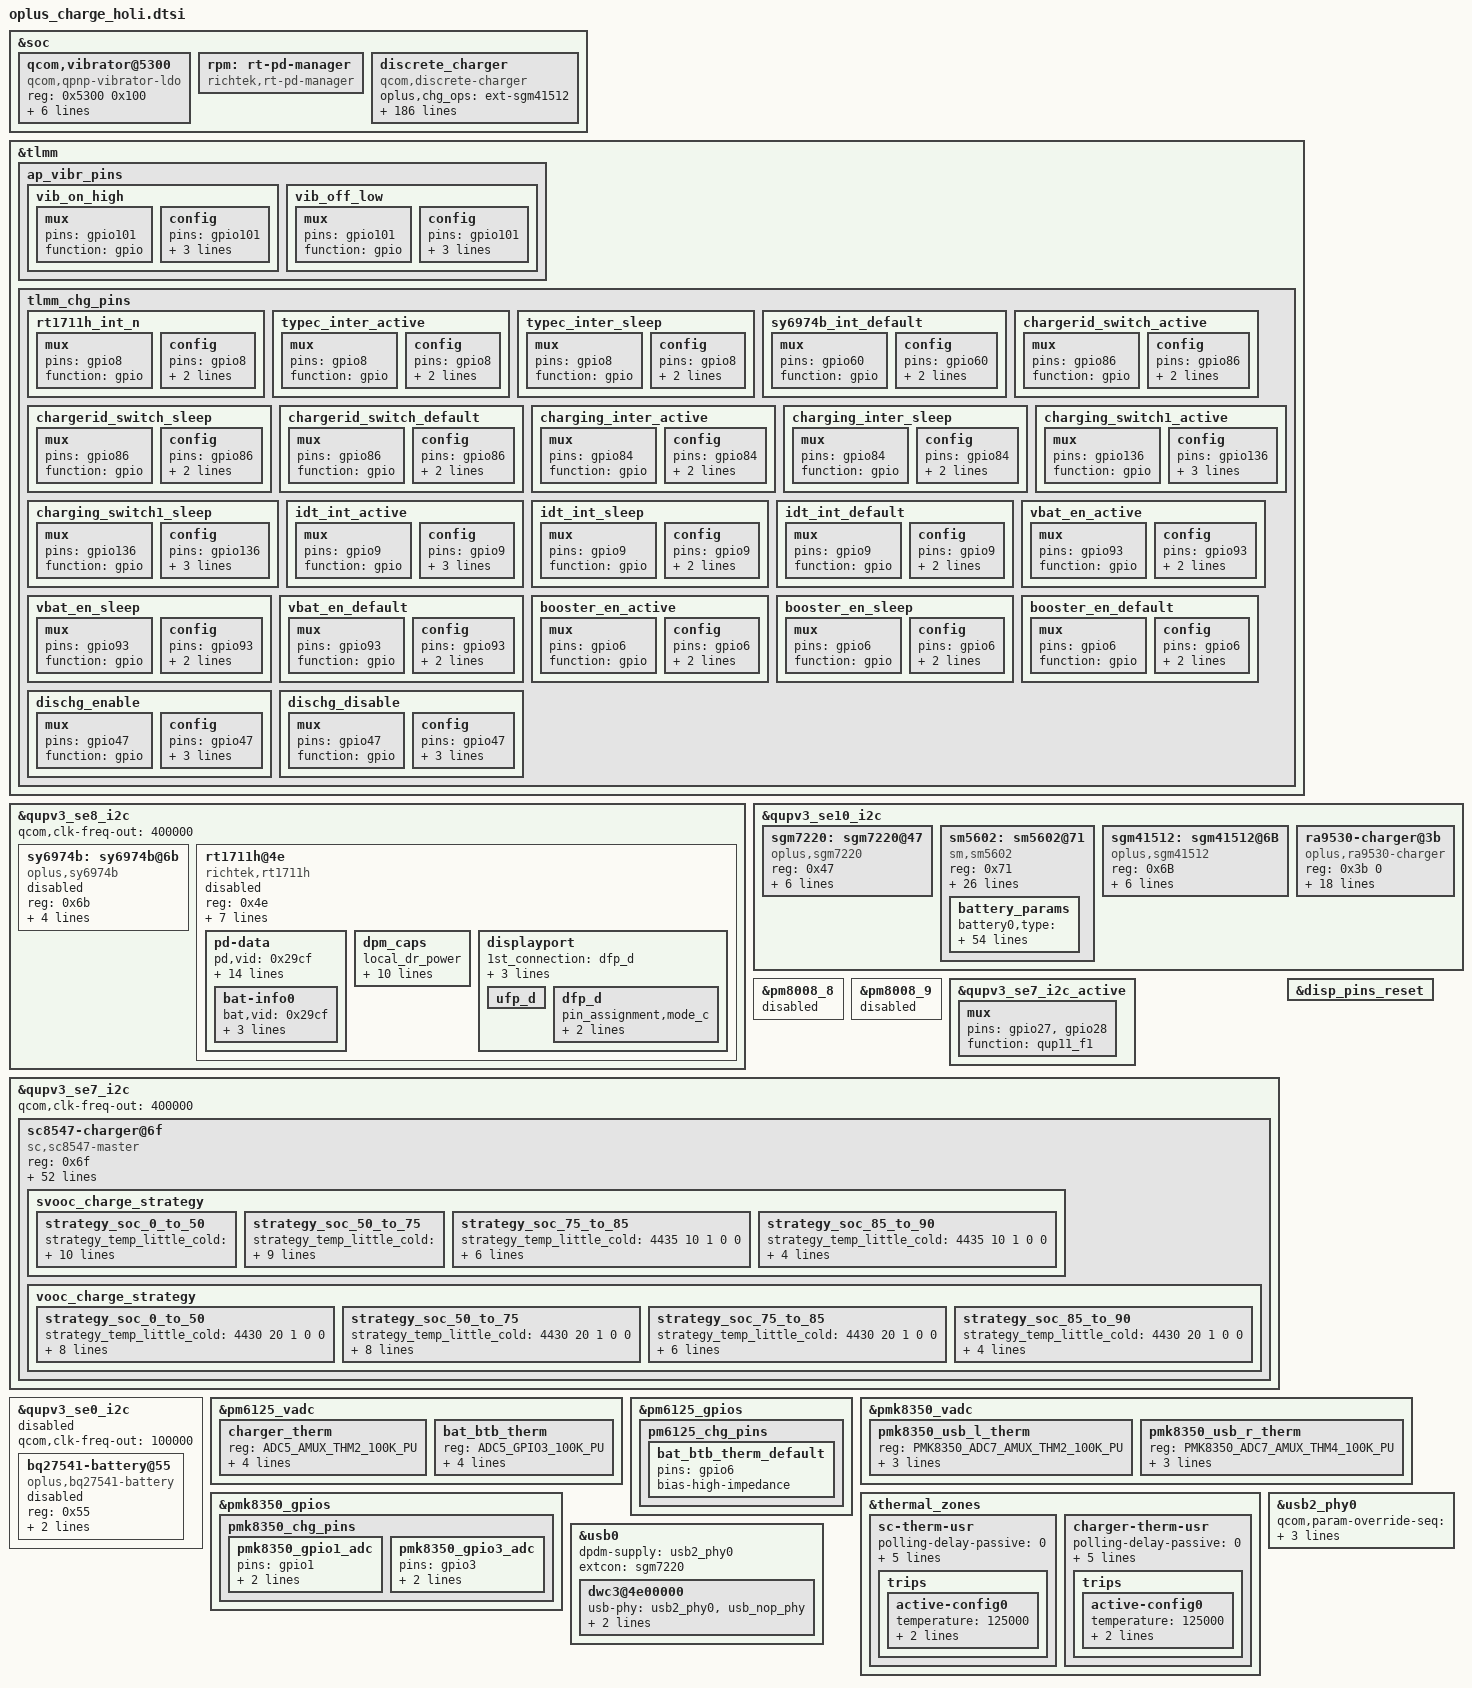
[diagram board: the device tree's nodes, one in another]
#include <dt-bindings/spmi/spmi.h>
#include <dt-bindings/iio/qcom,spmi-vadc.h>

&soc {
	qcom,vibrator@5300 {
		compatible = "qcom,qpnp-vibrator-ldo";
		reg = <0x5300 0x100>;
		qcom,vib-ldo-volt-uv = <3000000>;
		qcom,disable-overdrive;
		qcom,vib-type = <1>;	/*0:ldo 1:gpio*/
		status = "okay";

		qcom,vibrator_switch-gpio = <&tlmm 101 0x00>;
		pinctrl-names = "vib_on_high", "vib_off_low";
		pinctrl-0 = <&vib_on_high>;
		pinctrl-1 = <&vib_off_low >;
	};
};

&tlmm {

	ap_vibr_pins: ap_vibr_pins{
		vib_on_high: vib_on_high{
			mux {
				pins = "gpio101";
				function = "gpio";
			};

			config {
				pins = "gpio101";
				drive-strength = <2>;
				bias-disable;
				output-high;
			};
		};

		vib_off_low: vib_off_low{
			mux {
				pins = "gpio101";
				function = "gpio";
			};

			config {
				pins = "gpio101";
				drive-strength = <2>;
				bias-disable;
				output-high;
			};
		};
	};
};


&qupv3_se8_i2c {
	status = "okay";
	qcom,clk-freq-out = <400000>;
	sy6974b:sy6974b@6b {
		status = "disabled";
		compatible = "oplus,sy6974b";
		reg = <0x6b>;

		sy6974b-irq-gpio = <&tlmm 60 0x00>;
		dpdm-supply = <&usb2_phy0>;
		pinctrl-names = "default";
		pinctrl-0 = <&sy6974b_int_default>;
		qcom,use_real_suspend_6974b;
	};
	rt1711h@4e {
		compatible = "richtek,rt1711h";
		reg = <0x4e>;
		status = "disabled";
		tcpc-dual,supported_modes = <0>; /* 0: dfp/ufp, */
						 /* 1: dfp, 2: ufp */
		rt-tcpc,name = "type_c_port0"; /* tcpc_device's name */
		rt-tcpc,role_def = <1>; /* 0: Unknown, 1: SNK, 2: SRC */
					/* 3: DRP, 4: Try.SRC, 5: Try.SNK */
		rt-tcpc,rp_level = <0>; /* 0: Default, 1: 1.5, 2: 3.0 */
		rt-tcpc,vconn_supply  = <1>;  /* 0: Never, 1: Always, */
					      /* 2: EMarkOnly, 3: StartOnly */
		/* rt-tcpc,disable_pe; */
		//rt1711pd,intr_gpio = <&tlmm 124 0x0>;
		rt1711pd,intr_gpio_num = <124>;
		pinctrl-names = "default";
		pinctrl-0 = <&rt1711h_int_n>;
		pd-data {
			pd,vid = <0x29cf>;
			pd,pid = <0x1711>;
			pd,source-cap-ext = <0x171129cf 0x00000000 0x00000000
					     0x00000000 0x00000000 0x02000000>;
			pd,mfrs = "RichtekTCPC";

			/*
			 *	VSAFE5V = 0, MAX_POWER = 1, CUSTOM = 2,
			 *	MAX_POWER_LV = 0x21, MAX_POWER_LVIC = 0x31
			 *	MAX_POWER_HV = 0x41, MAX_POWER_HVIC = 0x51
			 */
			pd,charging_policy= <0x31>;

			/*
			 * Fixed 5V, 500 mA <0x00019032>
			 * Fixed 5V, 1A <0x00019064>
			 * Fixed 5V, 2A <0x000190c8>
			 * Fixed 5V, 3A <0x0001912c>
			 * Fixed 9V, 500 mA <0x0002d032>
			 * Fixed 9V, 1A <0x0002d064>
			 * Fixed 9V, 2A <0x0002d0c8>
			 * Fixed 9V, 3A <0x0002d12c>
			 * Variable 5-9V, 1A <0x8642d064>
			 * Variable 5-9V, 2A <0x8642d0c8>
			 * Variable 5-9V, 3A <0x8642d12c>
			 * PPS 3V~5.9V, 3A <0xC0761E3C>
			 */
			pd,source-pdo-size = <1>;
			pd,source-pdo-data = <0x00019032>;
			pd,sink-pdo-size = <1>;
			pd,sink-pdo-data = <0x000190c8>;

			/*
			 * No DP, host + device
			 *	pd,id-vdo-size = <6>;
			 *	pd,id-vdo-data = <0xd14029cf 0x0 0x17110000
						  0x41800000 0x0 0x21800000>;
			 * With DP
			 *	pd,id-vdo-size = <6>;
			 *	pd,id-vdo-data = <0xd54029cf 0x0 0x17110000
						  0x41800000 0x0 0x21800000>;
			 */

			pd,id-vdo-size = <6>;
			pd,id-vdo-data = <0xd14029cf 0x0 0x17110000
					  0x41800000 0x0 0x21800000>;

			bat,nr = <1>;
			pd,country_nr = <0>;

			bat-info0 {
				bat,vid = <0x29cf>;
				bat,pid = <0x1711>;
				bat,mfrs = "bat1";
				bat,design_cap = <3000>;
			};

			//bat-info1 {
			//	bat,vid = <0x8abc>;
			//	bat,pid = <0x5234>;
			//	bat,mfrs = "bat2";
			//	bat,design_cap = <4000>;
			//};

			//country0 {
			//	pd,country_code = <0x5457>;
			//	pd,country_len = <2>; /* max len = 26 */
			//	pd,country_data = <0xff 0xff>;
			//};

			//country1 {
			//	pd,country_code = <0x5553>;
			//	pd,country_len = <3>; /* max len = 26 */
			//	pd,country_data = <0xf1 0xf2 0xf3>;
			//};
		};
		dpm_caps {
			local_dr_power;
			local_dr_data;
			//local_ext_power;
			local_usb_comm;
			//local_usb_suspend;
			//local_high_cap;
			//local_give_back;
			local_no_suspend;
			local_vconn_supply;

			//attemp_discover_cable_dfp;
			attemp_enter_dp_mode;
			attemp_discover_cable;
			attemp_discover_id;
			attemp_discover_svid;

			/* 0: disable, 1: prefer_snk, 2: prefer_src */
			pr_check = <0>;
			//pr_reject_as_source;
			//pr_reject_as_sink;
			//pr_check_gp_source;
			//pr_check_gp_sink;

			/* 0: disable, 1: prefer_ufp, 2: prefer_dfp */
			dr_check = <0>;
			//dr_reject_as_dfp;
			//dr_reject_as_ufp;
		};
		displayport {
			/* connection type = "both", "ufp_d", "dfp_d" */
			1st_connection = "dfp_d";
			2nd_connection = "dfp_d";
			signal,dp_v13;
			//signal,dp_gen2;
			//usbr20_not_used;
			typec,receptacle;
			ufp_d {
				//pin_assignment,mode_a;
				//pin_assignment,mode_b;
				//pin_assignment,mode_c;
				//pin_assignment,mode_d;
				//pin_assignment,mode_e;
			};
			dfp_d {
				//pin_assignment,mode_a;
				//pin_assignment,mode_b;
				pin_assignment,mode_c;
				pin_assignment,mode_d;
				pin_assignment,mode_e;
				//pin_assignment,mode_f;
			};
		};
	};
};

/*
*CCLOGIC & SWITCH bring up for Tyr. Add by xukai@vanyol.com
*/
&qupv3_se10_i2c {
        status = "okay";
	sgm7220:sgm7220@47 {
                status = "okay";
                compatible = "oplus,sgm7220";
                reg = <0x47>;
                interrupt-parent = <&tlmm>;
                interrupts = <8 0>;
                interrupt-names = "sgm7220_int_irq";
                sgm7220,irq_gpio = <&tlmm 8 0x8008>;
                //sgm7220,reset-gpio = <&tlmm 12 0x0>;

                //typec irq
                pinctrl-names = "typec_inter_active", "typec_inter_sleep";
                pinctrl-0 = <&typec_inter_active>;
                pinctrl-1 = <&typec_inter_sleep>;

                //headphone det notifiy
                oplus,headphone-det-support = <1>;
       };

       sm5602:sm5602@71 {
		compatible = "sm,sm5602";
		reg = <0x71>;
		interrupt-parent = <&tlmm>;
		interrupts = <50 2>;
		qcom,irq-gpio = <&tlmm 50 0x0>;
		io-channels = <&pm6125_vadc ADC5_GPIO3_100K_PU>;
		io-channel-names = "bat_id_chan";
		sm,en_temp_ex;
		//sm,en_temp_in;
		sm,en_batt_det;
		//sm,iocv_man_mode;
		sm,misc = <0x0800>;
		sm,aging_ctrl = <0x0121>;
		sm,cycle_cfg = <0x7000>;
		sm,rsns = <0>;
		sm,fg_irq_set = <0x07FF>;
		sm,low_soc1 = <1>;
		sm,low_soc2 = <15>;
		sm,v_l_alarm = <3400>;
		sm,v_h_alarm = <4450>;
		sm,battery_table_num = <0>;
		sm,param_version = <4>;
		sm,t_l_alarm_in = <54>;
		sm,t_h_alarm_in = <1>;
		sm,t_l_alarm_ex = <0xD3D8>;
		sm,t_h_alarm_ex = <0x9245>;
		sm,rtrace = <4700>;
		sm,battery_id_num = <0 1>;
		sm,battery_id_resistance = <67 15>;
		sm,battery_id_temp = <33000 70000>;
		sm,check_battery_id;
		battery_params {
			battery0,type = "ATL 2868C7 1S2P 3.87V 8080mAh Rechargeable Li-ion Polymer Battery";
			battery0,param_version = <7>;
			battery0,max_voltage_uv = <4450000>;
			battery0,battery_type = <4450 0x0 0x3E88>;
			battery0,battery_table0 = <0x1400 0x1B33 0x1C25 0x1CEC 0x1D68 0x1D85 0x1D8E 0x1D92 0x1DD0 0x1E04 0x1E4E 0x1E6E 0x1EA6 0x1ED7 0x1F15 0x1F43 0x1F94 0x1FF1 0x2052 0x20F4 0x216D 0x2204 0x22FA 0x24CC>;
			battery0,battery_table1 = <0x0 0x66 0x199 0x334 0x4CF 0x5E1 0x916 0xAB1 0x100A 0x1563 0x1D68 0x22C1 0x2AC7 0x3020 0x3579 0x3826 0x3AD2 0x402B 0x4584 0x4D8A 0x52E3 0x594D 0x6400 0x64E6>;
			battery0,battery_table2 = <0x2A4D 0x181E 0x1214 0x0D0F 0x0B0C 0x0A0B 0x090A 0x0909>;
			battery0,alpha = <0x00CC>;
			battery0,beta = <0x0025>;
			battery0,rs = <0x005F>;
			battery0,rs_value = <0x0050 0x00DD 0x3800 0x0048>;
			battery0,vit_period = <0x315A>;
			battery0,volt_cal = <0x8000>;
			battery0,mix_value = <0x0003>;
			battery0,curr_offset = <0x000>;
			battery0,curr_slope = <0x8080>;
			battery0,topoff_soc = <7 1300 100>;
			battery0,temp_std = <25>;
			battery0,temp_offset = <0 11 1 0 8 (-1)>;
			battery0,temp_cal = <0 6 1 11 (-1) 0 6 1 9 1>;
			battery0,ext_temp_cal = <0 2 1 2 1 1 2 3 2 3>;
			battery0,tem_poff = <3400 100>;
			battery0,thermal_table = <0x3B3A 0x3516 0x2F05 0x28F4 0x2323 0x1D80 0x1804 0x12E1 0x0DA7 0x08B3
										0x03D6 0xF6F2 0xF273 0xEE03 0xE9D0 0xE5C7 0xE1E2 0xDE2C 0xDA98 0xD727
										0xD3D8 0xD0B2 0xCDAC 0xCAC8 0xC806 0xC55C 0xC2D0 0xC069 0xBE17 0xBBE1
										0xB9C6 0xB7C0 0xB5D3 0xB400 0xB242 0xB092 0xAEFD 0xAD7C 0xAC06 0xAAA6
										0xA953 0xA814 0xA6DE 0xA5BE 0xA4A5 0xA39C 0xA2A1 0xA1B1 0xA0CB 0x9FF3
										0x9F23 0x9E59 0x9D9A 0x9CE7 0x9C3B 0x9B95 0x9AF7 0x9A62 0x99D2 0x994B
										0x98CB 0x984E 0x97D6 0x9765 0x96FA 0x9693 0x9631 0x95D3 0x9579 0x9523
										0x94CF 0x9481 0x9435 0x93EC 0x93A6 0x9364 0x9325 0x92EA 0x92B1 0x927B
										0x9245 0x9212 0x91E1 0x91B2 0x9185 0x915A 0x9132 0x910B 0x90E6 0x90C2
										0x90A0 0x907E 0x905E 0x9040 0x9022 0x9006 0x8FEA 0x8FD0 0x8FB7 0x8FA0
										0x8F8A>;  					//NTC value(DEC) table -20~80
			battery1,type = "BLT005_CA2868C7FD_8080mAh";
			battery1,param_version = <4>;
			battery1,max_voltage_uv = <4450000>;
			battery1,battery_type = <4450 0x0 0x3FCD>;
			battery1,battery_table0 = <0x1400 0x1B31 0x1C0A 0x1D08 0x1D71 0x1D8C 0x1D95 0x1D9E 0x1DE6 0x1E3B 0x1E51 0x1E6B 0x1EA2 0x1ED1 0x1F12 0x1F46 0x1F88 0x1FE4 0x207A 0x2123 0x21DD 0x22A8 0x22F0 0x24CC>;
			battery1,battery_table1 = <0x0 0x6A 0x176 0x38F 0x522 0x7C1 0xAE6 0xC78 0x11B6 0x1C31 0x1ED0 0x240E 0x2BEB 0x3128 0x3666 0x3905 0x3BA4 0x40E2 0x48BE 0x509B 0x5878 0x60DA 0x6400 0x64E6>;
			battery1,battery_table2 = <0x2E54 0x1A21 0x1416 0x0F11 0x0C0D 0x0B0C 0x0A0A 0x0909>;
			battery1,alpha = <0x00CC>;
			battery1,beta = <0x0025>;
			battery1,rs = <0x005F>;
			battery1,rs_value = <0x0050 0x00DD 0x3800 0x0048>;
			battery1,vit_period = <0x315A>;
			battery1,volt_cal = <0x8000>;
			battery1,mix_value = <0x0003>;
			battery1,curr_offset = <0x000>;
			battery1,curr_slope = <0x8080>;
			battery1,topoff_soc = <7 1300 100>;
			battery1,temp_std = <25>;
			battery1,temp_offset = <0 11 1 0 8 (-1)>;
			battery1,temp_cal = <0 6 1 11 (-1) 0 6 1 9 1>;
			battery1,ext_temp_cal = <0 2 1 2 1 1 2 3 2 3>;
			battery1,tem_poff = <3400 100>;
			battery1,thermal_table = <0x3B3A 0x3516 0x2F05 0x28F4 0x2323 0x1D80 0x1804 0x12E1 0x0DA7 0x08B3
										0x03D6 0xF6F2 0xF273 0xEE03 0xE9D0 0xE5C7 0xE1E2 0xDE2C 0xDA98 0xD727
										0xD3D8 0xD0B2 0xCDAC 0xCAC8 0xC806 0xC55C 0xC2D0 0xC069 0xBE17 0xBBE1
										0xB9C6 0xB7C0 0xB5D3 0xB400 0xB242 0xB092 0xAEFD 0xAD7C 0xAC06 0xAAA6
										0xA953 0xA814 0xA6DE 0xA5BE 0xA4A5 0xA39C 0xA2A1 0xA1B1 0xA0CB 0x9FF3
										0x9F23 0x9E59 0x9D9A 0x9CE7 0x9C3B 0x9B95 0x9AF7 0x9A62 0x99D2 0x994B
										0x98CB 0x984E 0x97D6 0x9765 0x96FA 0x9693 0x9631 0x95D3 0x9579 0x9523
										0x94CF 0x9481 0x9435 0x93EC 0x93A6 0x9364 0x9325 0x92EA 0x92B1 0x927B
										0x9245 0x9212 0x91E1 0x91B2 0x9185 0x915A 0x9132 0x910B 0x90E6 0x90C2
										0x90A0 0x907E 0x905E 0x9040 0x9022 0x9006 0x8FEA 0x8FD0 0x8FB7 0x8FA0
										0x8F8A>;  //NTC value(DEC) table -20~80
	    };
	};
	sgm41512:sgm41512@6B {
	  status = "okay";
	  compatible = "oplus,sgm41512";
	  reg = <0x6B>;
	  interrupt-parent = <&tlmm>;
	  interrupts = <59 0>;
	  sgm41512-irq-gpio = <&tlmm 59 0>;
	  dpdm-supply = <&usb2_phy0>;
	  qcom,slave_charger_enable-gpio = <&tlmm 12 0x00>;
	  qcom,use_voocphy;
	};

	ra9530-charger@3b {
		status = "ok";
		compatible = "oplus,ra9530-charger";
		reg = <0x3b 0>;

		pinctrl-names = "idt_int_active", "idt_int_sleep", "idt_int_default",
						"vbat_en_active", "vbat_en_sleep", "vbat_en_default",
						"booster_en_active", "booster_en_sleep", "booster_en_default";

		pinctrl-0 = <&idt_int_active>;
		pinctrl-1 = <&idt_int_sleep>;
		pinctrl-2 = <&idt_int_default>;
		pinctrl-3 = <&vbat_en_active>;
		pinctrl-4 = <&vbat_en_sleep>;
		pinctrl-5 = <&vbat_en_default>;
		pinctrl-6 = <&booster_en_active>;
		pinctrl-7 = <&booster_en_sleep>;
		pinctrl-8 = <&booster_en_default>;

		qcom,idt_int-gpio = <&tlmm 9 0x00>;
		qcom,vbat_en-gpio = <&tlmm 93 0x00>;
		qcom,booster_en-gpio = <&tlmm 6 0x00>;

		qcom,ocp_threshold = <500>;
		qcom,ovp_threshold = <12000>;
		qcom,lvp_threshold = <4000>;
		qcom,pcop_threshold1 = <700>;
		qcom,pcop_threshold2 = <500>;
		qcom,fod_threshold = <400>;
	};
};

&soc {
	rpm: rt-pd-manager {
		compatible = "richtek,rt-pd-manager";
	};
};

&pm8008_8 {
	status = "disabled";
};

&pm8008_9 {
	status = "disabled";
};

&qupv3_se7_i2c_active {
	mux {
		pins = "gpio27", "gpio28";
		function = "qup11_f1";
	};
};

&qupv3_se7_i2c {
	status = "okay";
	qcom,clk-freq-out = <400000>;

	sc8547-charger@6f{
		status = "okay";
		compatible = "sc,sc8547-master";
		reg = <0x6f>;

		qcom,irq_gpio = <&tlmm 84 0x00>;
		interrupt-parent = <&tlmm>;
		interrupts = <84 0>;

		pinctrl-names = "switch1_act_switch2_act", "switch1_sleep_switch2_sleep",
				"charging_inter_active", "charging_inter_sleep";
		pinctrl-0 = <&charging_switch1_active>;
		pinctrl-1 = <&charging_switch1_sleep>;
		pinctrl-2 = <&charging_inter_active>;
		pinctrl-3 = <&charging_inter_sleep>;

		qcom,external_gauge_support;
		qcom,charging_switch1-gpio = <&tlmm 136 0x00>;

		qcom,voocphy_current_default = <30>;

		qcom,svooc_cool_down_current_limit = <100 20 20 20 30 40 50 60 70 80 90 100>;
		qcom,vooc_cool_down_current_limit = <60 20 20 20 30 40 50 60>;

		qcom,vooc_little_cold_full_voltage = <4430>;
		qcom,vooc_cool_full_voltage = <4430>;
		qcom,vooc_1time_full_voltage = <4480>;
		qcom,vooc_ntime_full_voltage = <4480>;
		qcom,low_curr_full_t1 = <120>;
		qcom,low_curr_full_t2 = <350>;
		qcom,low_curr_full_t3 = <430>;
		qcom,range1_low_curr_full = <1150 4470
						1050 4465
						950 4450
						850 4450
						750 4450>;
		qcom,range2_low_curr_full = <1550 4470
						1450 4465
						1350 4450
						1250 4450
						1150 4450>;

		qcom,vooc_multistep_initial_batt_temp = <1000>;
		qcom,vooc_little_cool_temp = <160>;
		qcom,vooc_cool_temp = <120>;
		qcom,vooc_little_cold_temp = <50>;
		qcom,vooc_normal_low_temp = <250>;
		qcom,vooc_strategy_normal_current = <60>;
		qcom,vooc_normal_to_little_cool_current = <60>;
		qcom,vooc_batt_over_high_temp = <440>;
		qcom,vooc_batt_over_low_temp = <0>;

		qcom,vooc_strategy1_batt_high_temp0 = <385>;
		qcom,vooc_strategy1_batt_high_temp1 = <395>;
		qcom,vooc_strategy1_batt_high_temp2 = <420>;
		qcom,vooc_strategy1_batt_low_temp2 = <410>;
		qcom,vooc_strategy1_batt_low_temp1 = <385>;
		qcom,vooc_strategy1_batt_low_temp0 = <375>;

		qcom,vooc_strategy1_high_current0 = <30>;
		qcom,vooc_strategy1_high_current1 = <30>;
		qcom,vooc_strategy1_high_current2 = <20>;
		qcom,vooc_strategy1_low_current2 = <20>;
		qcom,vooc_strategy1_low_current1 = <30>;
		qcom,vooc_strategy1_low_current0 = <30>;

		qcom,voocphy_ibat_over_current = <7500>;
		qcom,voocphy_cp_max_ibus = <3500>;

		svooc_batt_sys_curve =	<0 0 1 1 1 1 0	// 3000mA
					 0 0 0 0 0 0 1	// 3414mV
					 0 0 1 0 1 0 0	// 2000mA
					 1 1 1 0 0 1 0	// 4550mV
					 0 0 0 1 0 1 0	// 1000mA
					 1 1 1 0 0 1 0>;	// 4550mV

		vooc_batt_sys_curve =	<0 0 1 1 1 1 0	// 3000mA
					 0 0 0 0 0 0 1	// 3414mV
					 0 0 1 0 1 0 0	// 2000mA
					 1 1 1 0 0 1 0	// 4550mV
					 0 0 0 1 0 1 0	// 1000mA
					 1 1 1 0 0 1 0>;	// 4550mV

		svooc_charge_strategy {
			strategy_soc_0_to_50 {
				strategy_temp_little_cold =	<4180 18 0 0 0
								 4435 10 1 0 0>;
				strategy_temp_cool =   <4425 18 0 0 0
								 4425 14 0 0 0
								 4435 10 1 0 0>;
				strategy_temp_little_cool = <4460 25 0 0 0
								 4460 20 0 0 0
								 4460 15 0 0 0
								 4470 10 1 0 0>;
				strategy_temp_normal_low =	<4460 30 0 1200 0
								 4460 25 0 1200 0
								 4460 23 0 0 0
								 4460 20 0 0 0
								 4460 15 0 0 0
								 4470 10 1 0 0>;
				strategy_temp_normal_high =	<4460 30 0 1200 0
								 4460 25 0 1200 0
								 4460 23 0 0 0
								 4460 20 0 0 0
								 4460 15 0 0 0
								 4470 10 1 0 0>;
				strategy_temp_warm = <4130 10 1 0 0>;
			};

			strategy_soc_50_to_75 {
				strategy_temp_little_cold =	<4180 18 0 0 0
								 4435 10 1 0 0>;
				strategy_temp_cool =		<4425 18 0 0 0
								 4425 14 0 0 0
								 4435 10 1 0 0>;
				strategy_temp_little_cool =	<4460 25 0 0 0
								 4460 20 0 0 0
								 4460 15 0 0 0
								 4470 10 1 0 0>;
				strategy_temp_normal_low =	<4460 25 0 1200 0
								 4460 23 0 0 0
								 4460 20 0 0 0
								 4460 15 0 0 0
								 4470 10 1 0 0>;
				strategy_temp_normal_high =	<4460 25 0 1200 0
								 4460 23 0 0 0
								 4460 20 0 0 0
								 4460 15 0 0 0
								 4470 10 1 0 0>;
			};

			strategy_soc_75_to_85 {
				strategy_temp_little_cold = <4435 10 1 0 0>;
				strategy_temp_cool =		<4435 10 1 0 0>;
				strategy_temp_little_cool =	<4470 10 1 0 0>;
				strategy_temp_normal_low =	<4460 15 0 0 0
								4470 10 1 0 0>;
				strategy_temp_normal_high =	<4460 15 0 0 0
								4470 10 1 0 0>;
			};

			strategy_soc_85_to_90 {
				strategy_temp_little_cold = <4435 10 1 0 0>;
				strategy_temp_cool =		<4435 10 1 0 0>;
				strategy_temp_little_cool =	<4470 10 1 0 0>;
				strategy_temp_normal_low =	<4470 10 1 0 0>;
				strategy_temp_normal_high =	<4470 10 1 0 0>;
			};
		};

		vooc_charge_strategy {
			strategy_soc_0_to_50 {
				strategy_temp_little_cold =	<4430 20 1 0 0>;
				strategy_temp_cool =		<4420 30 0 0 0
								 4430 20 1 0 0>;
				strategy_temp_little_cool =	<4475 30 0 0 0
								 4480 20 1 0 0>;
				strategy_temp_normal_low =	<4475 30 0 0 0
								 4480 20 1 0 0>;
				strategy_temp_normal_high =	<4475 30 0 0 0
								 4480 20 1 0 0>;
			};

			strategy_soc_50_to_75 {
				strategy_temp_little_cold =	<4430 20 1 0 0>;
				strategy_temp_cool =		<4420 30 0 0 0
								 4430 20 1 0 0>;
				strategy_temp_little_cool =	<4475 30 0 0 0
								 4480 20 1 0 0>;
				strategy_temp_normal_low =	<4475 30 0 0 0
								 4480 20 1 0 0>;
				strategy_temp_normal_high =	<4475 30 0 0 0
								 4480 20 1 0 0>;
			};

			strategy_soc_75_to_85 {
				strategy_temp_little_cold =	<4430 20 1 0 0>;
				strategy_temp_cool =		<4430 20 1 0 0>;
				strategy_temp_little_cool =	<4480 20 1 0 0>;
				strategy_temp_normal_low =	<4475 30 0 0 0
								 4480 20 1 0 0>;
				strategy_temp_normal_high =	<4475 30 0 0 0
								 4480 20 1 0 0>;
			};

			strategy_soc_85_to_90 {
				strategy_temp_little_cold =	<4430 20 1 0 0>;
				strategy_temp_cool =		<4430 20 1 0 0>;
				strategy_temp_little_cool =	<4480 20 1 0 0>;
				strategy_temp_normal_low =	<4480 20 1 0 0>;
				strategy_temp_normal_high =	<4480 20 1 0 0>;
			};
		};
	};
};

&tlmm {
	tlmm_chg_pins: tlmm_chg_pins {
		rt1711h_int_n: rt1711h_int_n {
			mux {
				pins = "gpio8";
				function = "gpio";
			};

			config {
				pins = "gpio8";
				drive-strength = <2>;
				bias-disable;
			};
		};
		typec_inter_active: typec_inter_active {
            mux {
                 pins = "gpio8";
                 function = "gpio";
            };

            config {
                 pins = "gpio8";
                 drive-strength = <2>;
                 bias-pull-up;
                 };
        };
		typec_inter_sleep: typec_inter_sleep {
             mux {
                 pins = "gpio8";
                 function = "gpio";
             };

             config {
                 pins = "gpio8";
                 drive-strength = <2>;
                 bias-pull-up;
             };
        };

		sy6974b_int_default: sy6974b_int_default {
			mux {
				pins = "gpio60";
				function = "gpio";
			};

			config {
				pins = "gpio60";
				drive-strength = <2>;
				bias-disable;
			};
		};

		chargerid_switch_active: chargerid_switch_active {
			mux {
				pins = "gpio86";
				function = "gpio";
			};

			config {
				pins = "gpio86";
				drive-strength = <2>;
				bias-pull-up;
			};
		};

		chargerid_switch_sleep: chargerid_switch_sleep {
			mux {
				pins = "gpio86";
				function = "gpio";
			};

			config {
				pins = "gpio86";
				drive-strength = <2>;
				bias-pull-down;
			};
		};

		chargerid_switch_default: chargerid_switch_default {
			mux {
				pins = "gpio86";
				function = "gpio";
			};

			config {
				pins = "gpio86";
				drive-strength = <2>;
				bias-disable; /* NO PULL */
			};
		};

		charging_inter_active: charging_inter_active {
			mux {
				pins = "gpio84";
				function = "gpio";
			};

			config {
				pins = "gpio84";
				drive-strength = <2>;
				bias-disable; /* NO PULL */
			};
		};

		charging_inter_sleep: charging_inter_sleep {
			mux {
				pins = "gpio84";
				function = "gpio";
			};

			config {
				pins = "gpio84";
				drive-strength = <2>;
				bias-disable; /* NO PULL */
			};
		};
		charging_switch1_active: charging_switch1_active {
			mux {
				pins = "gpio136";
				function = "gpio";
			};

			config {
				pins = "gpio136";
				drive-strength = <2>;
				bias-disable;
				output-high;
			};
		};

		charging_switch1_sleep: charging_switch1_sleep {
			mux {
				pins = "gpio136";
				function = "gpio";
			};

			config {
				pins = "gpio136";
				drive-strength = <2>;
				bias-disable;
				output-low;
			};
		};

		idt_int_active: idt_int_active {
			mux {
				pins = "gpio9";
				function = "gpio";
			};

			config {
				pins = "gpio9";
				drive-strength = <2>;
				input-enable;
				bias-pull-up;
			};
		};

		idt_int_sleep: idt_int_sleep {
		       mux {
			       pins = "gpio9";
			       function = "gpio";
		       };

		       config {
			       pins = "gpio9";
			       drive-strength = <2>;
			       bias-disable;
		       };
	       };

		idt_int_default: idt_int_default {
			 mux {
				 pins = "gpio9";
				 function = "gpio";
			 };

			 config {
				 pins = "gpio9";
				 drive-strength = <2>;
				 bias-pull-up;
			 };
		 };

		vbat_en_active: vbat_en_active {
			mux {
				pins = "gpio93";
				function = "gpio";
			};

			config {
				pins = "gpio93";
				drive-strength = <2>;
				bias-pull-up;
			};
		};

		vbat_en_sleep: vbat_en_sleep {
		       mux {
			       pins = "gpio93";
			       function = "gpio";
		       };

		       config {
			       pins = "gpio93";
			       drive-strength = <2>;
			       bias-pull-down;
		       };
	       };

		vbat_en_default: vbat_en_default {
			 mux {
				 pins = "gpio93";
				 function = "gpio";
			 };

			 config {
				 pins = "gpio93";
				 drive-strength = <2>;
				 bias-pull-up;
			 };
		 };

		booster_en_active: booster_en_active {
			   mux {
				   pins = "gpio6";
				   function = "gpio";
			   };

			   config {
				   pins = "gpio6";
				   drive-strength = <2>;
				   bias-pull-up;
			   };
		   };

		booster_en_sleep: booster_en_sleep {
			  mux {
				  pins = "gpio6";
				  function = "gpio";
			  };

			  config {
				  pins = "gpio6";
				  drive-strength = <2>;
				  bias-pull-down;
			  };
		  };

		booster_en_default: booster_en_default {
			    mux {
				    pins = "gpio6";
				    function = "gpio";
			    };

			    config {
				    pins = "gpio6";
				    drive-strength = <2>;
				    bias-pull-up;
			    };
		    };

		dischg_enable: dischg_enable {
			mux {
				pins = "gpio47";
				function = "gpio";
			};

			config {
				pins = "gpio47";
				drive-strength = <2>;
				bias-disable;
				output-high;
			};
		};

		dischg_disable: dischg_disable {
			mux {
				pins = "gpio47";
				function = "gpio";
			};

			config {
				pins = "gpio47";
				drive-strength = <2>;
				bias-disable;
				output-low;
			};
		};
	};
};

&qupv3_se0_i2c {
	status = "disabled";
	qcom,clk-freq-out = <100000>;

	bq27541-battery@55 {
		status = "disabled";
		compatible = "oplus,bq27541-battery";
		reg = <0x55>;
		qcom,modify-soc-smooth;
		qcom,modify-soc-calibration;
	};
};

&disp_pins_reset {
	/delete-property/ pins;
	/delete-property/ function;
	/delete-property/ qcom,drive-strength;
	/delete-property/ power-source;
	/delete-property/ bias-disable;
	/delete-property/ output-low;
};

&pm6125_vadc {
	charger_therm {
		reg = <ADC5_AMUX_THM2_100K_PU>;
		label = "charger_therm";
		qcom,ratiometric;
		qcom,hw-settle-time = <200>;
		qcom,pre-scaling = <1 1>;
	};

	bat_btb_therm {
		reg = <ADC5_GPIO3_100K_PU>;
		label = "bat_btb_therm";
		qcom,ratiometric;
		qcom,hw-settle-time = <200>;
		qcom,pre-scaling = <1 1>;
	};
};

&pm6125_gpios {
	pm6125_chg_pins: pm6125_chg_pins {
		bat_btb_therm_default: bat_btb_therm_default {
			pins = "gpio6";
			bias-high-impedance;
		};
	};
};

&pmk8350_vadc {
	pmk8350_usb_l_therm: pmk8350_usb_l_therm {
		reg = <PMK8350_ADC7_AMUX_THM2_100K_PU>;
		label = "pmk8350_usb_l_therm";
		qcom,pre-scaling = <1 1>;
		qcom,scale-fn-type = <ADC_SCALE_HW_CALIB_DEFAULT>;
	};

	pmk8350_usb_r_therm: pmk8350_usb_r_therm {
		reg = <PMK8350_ADC7_AMUX_THM4_100K_PU>;
		label = "pmk8350_usb_r_therm";
		qcom,pre-scaling = <1 1>;
		qcom,scale-fn-type = <ADC_SCALE_HW_CALIB_DEFAULT>;
	};
};

&pmk8350_gpios {
	pmk8350_chg_pins: pmk8350_chg_pins {
		pmk8350_gpio1_adc: pmk8350_gpio1_adc {
			pins = "gpio1"; /* GPIO 1 */
			function = "normal"; /* normal */
			bias-high-impedance; /* DISABLE GPIO1 for ADC*/
		};

		pmk8350_gpio3_adc: pmk8350_gpio3_adc {
			pins = "gpio3"; /* GPIO 3 */
			function = "normal"; /* normal */
			bias-high-impedance; /* DISABLE GPIO3 for ADC*/
		};
	};
};


&thermal_zones {
	sc-therm-usr {
		polling-delay-passive = <0>;
		polling-delay = <0>;
		thermal-governor = "user_space";
		thermal-sensors = <&pm6125_adc_tm_iio ADC5_GPIO2_100K_PU>;
		wake-capable-sensor;
		trips {
			active-config0 {
				temperature = <125000>;
				hysteresis = <1000>;
				type = "passive";
			};
		};
	};

	charger-therm-usr {
		polling-delay-passive = <0>;
		polling-delay = <0>;
		thermal-governor = "user_space";
		thermal-sensors = <&pm6125_adc_tm_iio ADC5_GPIO1_100K_PU>;
		wake-capable-sensor;
		trips {
			active-config0 {
				temperature = <125000>;
				hysteresis = <1000>;
				type = "passive";
			};
		};
	};
};

&soc {
	discrete_charger: discrete_charger {
		compatible = "qcom,discrete-charger";
		status = "okay";

		oplus,chg_ops = "ext-sgm41512";
		#io-channel-cells = <1>;
		io-channels = <&pmk8350_vadc PMK8350_ADC7_AMUX_THM2_100K_PU>,
					  <&pmk8350_vadc PMK8350_ADC7_AMUX_THM4_100K_PU>,
					  <&pm6125_vadc ADC5_XO_THERM_100K_PU>,
					  <&pm6125_vadc ADC5_AMUX_THM2_100K_PU>;
		io-channel-names = "usbtemp_r_v_chan",
						   "usbtemp_l_v_chan",
						   "usbbtb_temp_chan",
						   "batbtb_temp_chan";

		pinctrl-names = "default",
						"chargerid_switch_active", "chargerid_switch_sleep", "chargerid_switch_default",
						"dischg_enable", "dischg_disable",
						"2uart_active", "2uart_sleep";

		pinctrl-0 = <&bat_btb_therm_default
					 &pmk8350_gpio1_adc
					 &pmk8350_gpio3_adc
					>;
		pinctrl-1 = <&chargerid_switch_active>;
		pinctrl-2 = <&chargerid_switch_sleep>;
		pinctrl-3 = <&chargerid_switch_default>;
		pinctrl-4 = <&dischg_enable>;
		pinctrl-5 = <&dischg_disable>;
		pinctrl-6 = <&qupv3_se9_2uart_active>;
		pinctrl-7 = <&qupv3_se9_2uart_sleep>;

		qcom,input_current_charger_ma = <2000>;
		qcom,pd_input_current_charger_ma = <2000>;
		qcom,qc_input_current_charger_ma = <2000>;
		qcom,input_current_usb_ma = <500>;
		qcom,input_current_cdp_ma = <1500>;
		qcom,input_current_camera_ma = <1200>;
		qcom,input_current_calling_ma = <1500>;

		qcom,led_warm_bat_decidegc = <350>;
		qcom,led_high_bat_decidegc = <370>;
		qcom,input_current_led_ma = <1200>;
		qcom,input_current_led_ma_high = <1500>;
		qcom,input_current_led_ma_warm = <1800>;
		qcom,input_current_led_ma_normal = <2000>;

		qcom,vooc_temp_bat_normal_decidegc = <350>;
		qcom,vooc_temp_bat_warm_decidegc = <370>;
		qcom,vooc_temp_bat_hot_decidegc = <440>;
		qcom,input_current_vooc_led_ma_high = <1200>;
		qcom,input_current_vooc_led_ma_warm = <1800>;
		qcom,input_current_vooc_led_ma_normal = <3600>;
		qcom,input_current_vooc_ma_normal = <3600>;

		qcom,input_current_vooc_ma_warm = <3200>;

		qcom,input_current_vooc_ma_high = <2200>;

		qcom,charger_current_vooc_ma_normal = <1800>;

		qcom,overtemp_bat_decidegc = <350>;
		qcom,iterm_disabled = <0>;
		qcom,iterm_ma = <420>;
		qcom,recharge-mv = <100>;
		qcom,batt_capacity_mah = <5000>;/*typical capacity*/

		qcom,removed_bat_decidegc = <190>;  /*<-19C*/

		qcom,cold_bat_decidegc = <100>;  /*-10C~0C*/
		qcom,temp_cold_vfloat_mv = <4435>;
		qcom,temp_cold_fastchg_current_ma = <1600>;
		qcom,temp_cold_fastchg_current_ma_high = <1600>;
		qcom,temp_cold_fastchg_current_ma_low = <1200>;
		qcom,pd_temp_cold_fastchg_current_ma_high = <1600>;
		qcom,pd_temp_cold_fastchg_current_ma_low = <1200>;
		qcom,qc_temp_cold_fastchg_current_ma_high = <1600>;
		qcom,qc_temp_cold_fastchg_current_ma_low = <1200>;

		qcom,little_cold_bat_decidegc = <0>;	/*0C~5C*/
		qcom,temp_little_cold_vfloat_mv = <4435>;
		qcom,temp_little_cold_fastchg_current_ma_high = <2200>;
		qcom,temp_little_cold_fastchg_current_ma_low = <2000>;
		qcom,temp_little_cold_fastchg_current_ma = <2200>;
		qcom,pd_temp_little_cold_fastchg_current_ma_high = <3000>;
		qcom,pd_temp_little_cold_fastchg_current_ma_low = <2000>;
		qcom,qc_temp_little_cold_fastchg_current_ma_high = <3000>;
		qcom,qc_temp_little_cold_fastchg_current_ma_low = <2000>;

		qcom,cool_bat_decidegc = <50>;	/*5C~12C*/
		qcom,temp_cool_vfloat_mv = <4435>;
		qcom,temp_cool_fastchg_current_ma_high = <2200>;
		qcom,temp_cool_fastchg_current_ma_low = <2200>;
		qcom,pd_temp_cool_fastchg_current_ma_high = <3000>;
		qcom,pd_temp_cool_fastchg_current_ma_low = <3000>;
		qcom,qc_temp_cool_fastchg_current_ma_high = <3000>;
		qcom,qc_temp_cool_fastchg_current_ma_low = <3000>;

		qcom,little_cool_bat_decidegc = <120>;	/*12C~16C*/
		qcom,temp_little_cool_vfloat_mv = <4435>;
		qcom,temp_little_cool_fastchg_current_ma = <2200>;
		qcom,pd_temp_little_cool_fastchg_current_ma = <3000>;
		qcom,qc_temp_little_cool_fastchg_current_ma = <3000>;

		qcom,normal_bat_decidegc = <160>;	/*16C~45C*/
		qcom,temp_normal_fastchg_current_ma = <2200>;
		qcom,temp_normal_vfloat_mv = <4435>;
		qcom,pd_temp_normal_fastchg_current_ma = <3000>;
		qcom,qc_temp_normal_fastchg_current_ma = <3000>;

		qcom,warm_bat_decidegc = <450>;		/*45C~53C*/ /*8pin Bat Vooc project need add 3 degree C*/
		qcom,temp_warm_vfloat_mv = <4130>;
		qcom,temp_warm_fastchg_current_ma = <2000>;
		qcom,pd_temp_warm_fastchg_current_ma = <1000>;
		qcom,qc_temp_warm_fastchg_current_ma = <1000>;
		qcom,temp_warm_fastchg_current_ma_led_on = <1000>;

		qcom,hot_bat_decidegc = <530>;

		qcom,non_standard_vfloat_mv = <3980>;
		qcom,non_standard_fastchg_current_ma = <512>;

		qcom,short_c_bat_cv_mv = <4330>;
		qcom,short_c_bat_vfloat_mv = <3800>;
		qcom,short_c_bat_fastchg_current_ma = <512>;

		qcom,cold_vfloat_sw_limit = <4385>;
		qcom,little_cold_vfloat_sw_limit = <4385>;
		qcom,cool_vfloat_sw_limit = <4385>;
		qcom,little_cool_vfloat_sw_limit = <4385>;
		qcom,normal_vfloat_sw_limit = <4385>;
		qcom,warm_vfloat_sw_limit = <4080>;
		qcom,non_standard_vfloat_sw_limit = <3930>;
		qcom,short_c_bat_vfloat_sw_limit = <3750>;

		qcom,max_chg_time_sec = <64800>;
		qcom,charger_hv_thr = <10000>;
		qcom,charger_recv_thr = <9800>;
		qcom,charger_lv_thr = <3400>;
		qcom,vbatt_full_thr = <4435>;
		qcom,vbatt_hv_thr = <4600>;

		qcom,vfloat_step_mv = <8>;
		qcom,cold_vfloat_over_sw_limit = <4445>;
		qcom,little_cold_vfloat_over_sw_limit = <4445>;
		qcom,cool_vfloat_over_sw_limit = <4445>;
		qcom,little_cool_vfloat_over_sw_limit = <4445>;
		qcom,normal_vfloat_over_sw_limit = <4445>;
		qcom,warm_vfloat_over_sw_limit = <4140>;
		qcom,non_standard_vfloat_over_sw_limit = <3990>;

		qcom,vbatt_power_off = <3300>;
		qcom,vbatt_soc_1 = <3310>;
		qcom,vooc_project = <5>;
		qcom,vbatt_num = <1>;
		qcom,new_ui_warning_support;
		qcom,voocphy_support = <2>;
		voocphy_support_display_vooc;
		qcom,chargerid_support;
		qcom,ffc_support;
		qcom,dual_ffc;
		qcom,smart_charging_screenoff;
		qcom,vooc_show_ui_soc_decimal;
		qcom,ui_soc_decimal_speedmin = <20>;//2A
		qcom,check_batt_full_by_sw;
		qcom,chg_ctrl_by_lcd;
		qcom,chg_ctrl_by_camera;
		qcom,chg_ctrl_by_calling;
		qcom,use_external_cclogic;

		qcom,sw_vfloat_over_protect_enable;

		qcom,normal_vterm_hw_inc = <18>;
		qcom,non_normal_vterm_hw_inc = <18>;
		qcom,usbtemp_batttemp_gap = <12>;

		qcom,ff1_normal_fastchg_ma = <1500>;
		qcom,ff1_warm_fastchg_ma = <1700>;

		qcom,ffc2_normal_fastchg_ma = <1200>;/*12C~35c*/
		qcom,ffc2_temp_warm_decidegc = <350>;
		qcom,ffc2_warm_fastchg_ma = <1700>;/*35C~40c*/
		qcom,ffc2_temp_high_decidegc = <400>;
		qcom,ffc2_temp_low_decidegc = <120>;
		qcom,ffc2_exit_step_ma = <150>;
		qcom,ffc2_warm_exit_step_ma = <250>;
		qcom,ff1_exit_step_ma = <450>;
		qcom,ff1_warm_exit_step_ma = <250>;

		qcom,ffc_normal_vfloat_sw_limit = <4465>;
		qcom,ffc2_normal_vfloat_sw_limit = <4465>;
		qcom,ffc2_warm_vfloat_sw_limit = <4465>;

		qcom,ffc_temp_normal_vfloat_mv = <4550>;
		qcom,ffc1_temp_normal_vfloat_mv = <4550>;
		qcom,ffc2_temp_normal_vfloat_mv = <4550>;
		qcom,ffc_normal_vfloat_over_sw_limit = <4650>;
		qcom,ffc1_normal_vfloat_over_sw_limit = <4650>;
		qcom,ffc2_normal_vfloat_over_sw_limit = <4650>;

		qcom,default_iterm_ma = <420>;
		qcom,default_temp_normal_fastchg_current_ma = <2200>;
		qcom,default_normal_vfloat_sw_limit = <4385>;
		qcom,default_temp_normal_vfloat_mv = <4435>;
		qcom,default_normal_vfloat_over_sw_limit = <4445>;

		qcom,default_temp_little_cool_fastchg_current_ma = <2200>;
		qcom,default_little_cool_vfloat_sw_limit = <4385>;
		qcom,default_temp_little_cool_vfloat_mv = <4435>;
		qcom,default_little_cool_vfloat_over_sw_limit = <4445>;

		//for PD9V or QC9V
		qcom,vbatt_pdqc_to_5v_thr = <4500>;
		qcom,vbatt_pdqc_to_9v_thr = <4500>;

		//GPIO config:
		qcom,chargerid_switch-gpio = <&tlmm 86 0x00>;
		qcom,dischg-gpio = <&tlmm 47 0x00>;
		qcom,cclogic-gpio = <&tlmm 124 0x00>;


		qcom,vooc-max-input-volt-support = <10000>;     //10V
		qcom,vooc-max-input-current-support = <3000>;   //3A
	};
};

&usb0 {
	dpdm-supply = <&usb2_phy0>;
	extcon = <&sgm7220>;
	dwc3@4e00000 {
		usb-phy = <&usb2_phy0>, <&usb_nop_phy>;
		maximum-speed = "high-speed";
		dr_mode = "otg";
	};
};

&usb2_phy0 {
	qcom,param-override-seq =
		<0xe6 0x6c	/* override_x0 */
		 0xcc 0x70	/* override_x1 */
		 0x17 0x74	/* override x2 */
		 0x03 0x78>;	/* override x2 */
	qcom,param-override-host-seq =
		<0xe6 0x6c	/* override_x0 */
		 0xcc 0x70	/* override_x1 */
		 0x17 0x74	/* override x2 */
		 0x03 0x78>;	/* override x2 */
};
